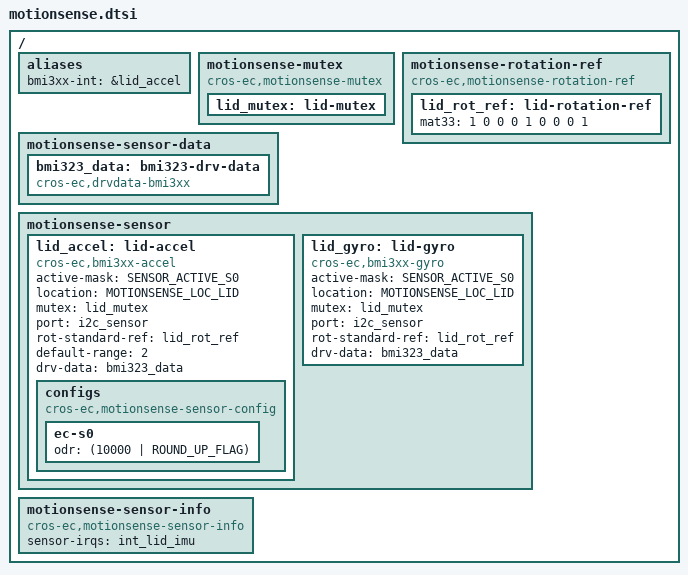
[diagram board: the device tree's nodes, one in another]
/* Copyright 2020 The ChromiumOS Authors
 * Use of this source code is governed by a BSD-style license that can be
 * found in the LICENSE file.
 */

#include <dt-bindings/motionsense/utils.h>


/ {
	aliases {
		/*
		 * motion sense's <>_INT_EVENT is handled
		 * by alias. Using the alias, each driver creates
		 * its own <>_INT_EVENT.
		 */
		bmi3xx-int = &lid_accel;
	};

	/*
	 * Declare mutexes used by sensor drivers.
	 * A mutex node is used to create an instance of mutex_t.
	 * A mutex node is referenced by a sensor node if the
	 * corresponding sensor driver needs to use the
	 * instance of the mutex.
	 */
	motionsense-mutex {
		compatible = "cros-ec,motionsense-mutex";
		lid_mutex: lid-mutex {
		};
	};

	/* Rotation matrix used by drivers. */
	motionsense-rotation-ref {
		compatible = "cros-ec,motionsense-rotation-ref";
		lid_rot_ref: lid-rotation-ref {
			mat33 = <1 0 0
				 0 1 0
				 0 0 1>;
		};
	};

	/*
	 * Driver specific data. A driver-specific data can be shared with
	 * different motion sensors while they are using the same driver.
	 *
	 * If a node's compatible starts with "cros-ec,accelgyro-", it is for
	 * a common structure defined in accelgyro.h.
	 * e.g) compatible = "cros-ec,accelgyro-als-drv-data" is for
	 * "struct als_drv_data_t" in accelgyro.h
	 */
	motionsense-sensor-data {
		bmi323_data: bmi323-drv-data {
			compatible = "cros-ec,drvdata-bmi3xx";
			status = "okay";
		};
	};

	/*
	 * List of motion sensors that creates motion_sensors array.
	 * The nodelabel "lid_accel" and "base_accel" are used to indicate
	 * motion sensor IDs for lid angle calculation.
	 */
	motionsense-sensor {
		lid_accel: lid-accel {
			compatible = "cros-ec,bmi3xx-accel";
			status = "okay";

			active-mask = "SENSOR_ACTIVE_S0";
			location = "MOTIONSENSE_LOC_LID";
			mutex = <&lid_mutex>;
			port = <&i2c_sensor>;
			rot-standard-ref = <&lid_rot_ref>;
			default-range = <2>;
			drv-data = <&bmi323_data>;
			configs {
				compatible =
					"cros-ec,motionsense-sensor-config";
				ec-s0 {
					odr = <(10000 | ROUND_UP_FLAG)>;
				};
			};
		};

		lid_gyro: lid-gyro {
			compatible = "cros-ec,bmi3xx-gyro";
			status = "okay";

			active-mask = "SENSOR_ACTIVE_S0";
			location = "MOTIONSENSE_LOC_LID";
			mutex = <&lid_mutex>;
			port = <&i2c_sensor>;
			rot-standard-ref = <&lid_rot_ref>;
			drv-data = <&bmi323_data>;
		};
	};

	motionsense-sensor-info {
		compatible = "cros-ec,motionsense-sensor-info";

		/*
		 * list of GPIO interrupts that have to
		 * be enabled at initial stage
		 */
		sensor-irqs = <&int_lid_imu>;
	};
};
